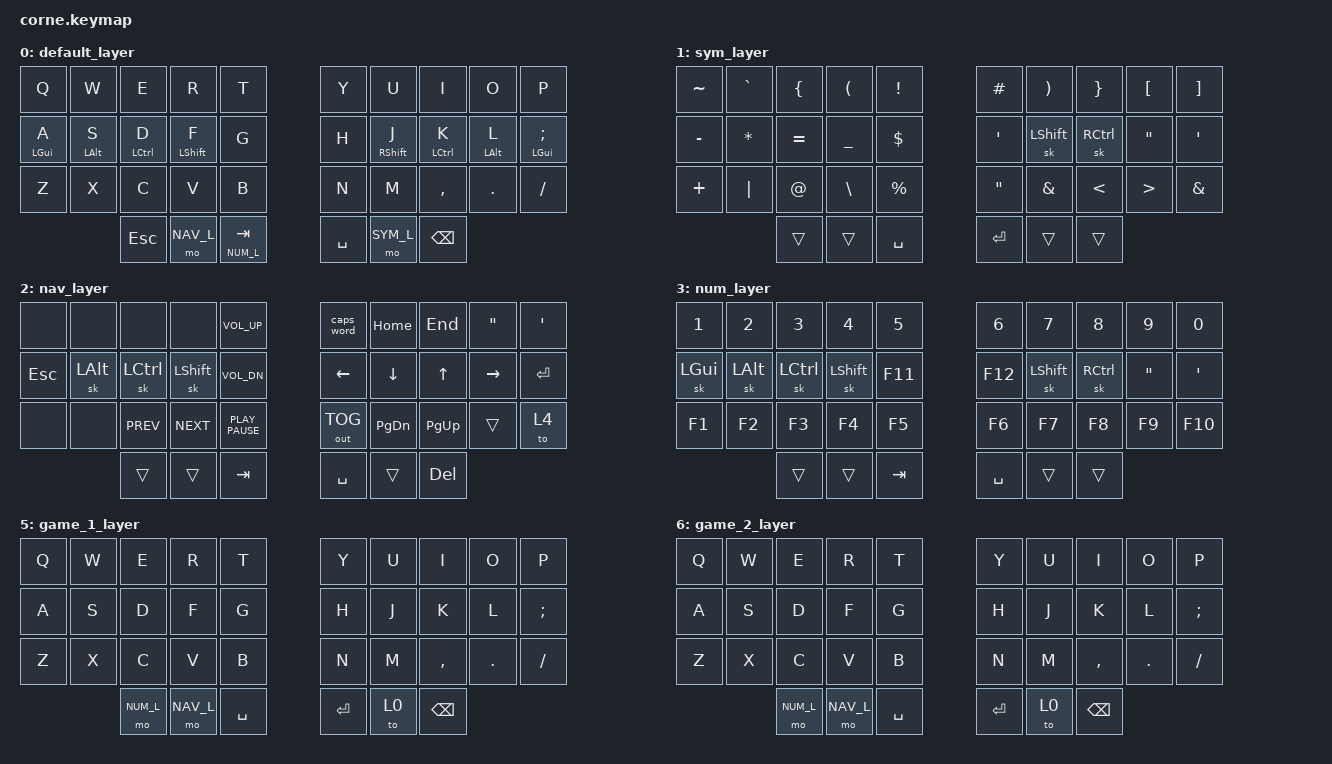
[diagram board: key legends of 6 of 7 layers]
#include <behaviors.dtsi>
#include <dt-bindings/zmk/keys.h>
#include <dt-bindings/zmk/bt.h>
#include <dt-bindings/zmk/outputs.h>

#define QUICK_TAP_MS 175

#define XXX &none
#define ___ &trans

&sk {  // sticky-key config
    release-after-ms = <900>;  // release after 0.6s
    quick-release;             // no double capitalization when rolling keys
};

&sl {  // sticky-layer config
    ignore-modifiers;          // allow chording sticky mods & layers
};

&lt {  // layer-tap config
    flavor = "balanced";
    tapping-term-ms = <200>;
    quick-tap-ms = <QUICK_TAP_MS>;
};

&caps_word {
    continue-list = <UNDERSCORE MINUS>;
};

#include "keys.h"
#define KEYS_L LT0 LT1 LT2 LT3 LT4 LM0 LM1 LM2 LM3 LM4 LB0 LB1 LB2 LB3 LB4  // left hand
#define KEYS_R RT0 RT1 RT2 RT3 RT4 RM0 RM1 RM2 RM3 RM4 RB0 RB1 RB2 RB3 RB4  // right hand
#define THUMBS LH2 LH1 LH0 RH0 RH1 RH2                                      // thumbs

#define _BT_SEL_KEYS_1_ &bt BT_SEL 0 &bt BT_SEL 1 &bt BT_SEL 2  &bt BT_SEL 3
#define _BT_SEL_KEYS_2_ &bt BT_CLR_ALL &bt BT_CLR

#define DEF_L 0 
#define SYM_L 1 
#define NAV_L 2 
#define NUM_L 3 
#define CON_L 4 
#define GAME_1_L 5 
#define GAME_2_L 6 


/ {

    chosen { zmk,matrix_transform = &five_column_transform; };

    behaviors {
        hml: hml {
            compatible = "zmk,behavior-hold-tap";
            #binding-cells = <2>;
            flavor = "balanced";
            tapping-term-ms = <280>;
            quick-tap-ms = <QUICK_TAP_MS>;
            require-prior-idle-ms = <75>;
            bindings = <&kp>, <&kp>;
            hold-trigger-key-positions = <KEYS_R THUMBS>;
            hold-trigger-on-release;
        };


        hmr: hmr {
            compatible = "zmk,behavior-hold-tap";
            #binding-cells = <2>;
            flavor = "balanced";
            tapping-term-ms = <280>;
            quick-tap-ms = <QUICK_TAP_MS>;
            require-prior-idle-ms = <75>;
            bindings = <&kp>, <&kp>;
            hold-trigger-key-positions = <KEYS_L THUMBS>;
            hold-trigger-on-release;
        };
    };

    keymap {
        compatible = "zmk,keymap";

        default_layer {
// ----------------------------------------------------------------------------
// |  Q  |  W  |  E  |  R  |  T  |   |  Y  |  U   |  I   |  O  |  P  |
// |  A  |  S  |  D  |  F  |  G  |   |  H  |  J   |  K   |  L  |  ;  |
// |  Z  |  X  |  C  |  V  |  B  |   |  N  |  M   |  ,   |  .  |  /  |
//             | esc | LWR | tab |   | spc | RSE  | bksp |
        bindings = <
   &kp Q       &kp W       &kp E         &kp R        &kp T           &kp Y     &kp U        &kp I        &kp O       &kp P   
   &hml LGUI A &hml LALT S &hml LCTRL D  &hml LSHFT F &kp G           &kp H     &hmr RSHFT J &hmr LCTRL K &hmr LALT L &hmr LGUI SEMI
   &kp Z       &kp X       &kp C         &kp V        &kp B           &kp N     &kp M        &kp COMMA    &kp DOT     &kp FSLH
                           &kp ESC       &mo NAV_L    &lt NUM_L TAB   &kp SPACE &mo SYM_L    &kp BSPC
                   >;
        };

        sym_layer {

// ---------------------------------------------------------------------------
// | esc | ~   | `   | ( | {   |   | }    | )   | [    | ]    | ^     |
// | -   | *   | =   | _ | $   |   | #    | cmd | alt  | ctrl | shift |
// | +   | "|" | @   | \ | %   |   | none | !   | &    | '    | "     |
//             | esc |   | tab |   | spc  |     | bspc |


            bindings = <
   &kp TILDE  &kp GRAVE  &kp LBRC   &kp LPAR   &kp EXCL   &kp HASH &kp RPAR    &kp RBRC   &kp LBKT  &kp RBKT
   &kp MINUS  &kp ASTRK  &kp EQUAL  &kp UNDER  &kp DLLR   &kp SQT  &sk LSHIFT  &sk RCTRL  &kp DQT   &kp SQT
   &kp PLUS   &kp PIPE   &kp AT     &kp BSLH   &kp PRCNT  &kp DQT  &kp AMPS    &kp LT     &kp GT    &kp AMPS  
                         ___        ___        &kp SPACE  &kp RET   ___         ___
                       >;
        };

        nav_layer {
// ---------------------------------------------------------------------------
// | bt0  | bt1  | bt2  | bt3  | volup |   | cpsword | home | end  | del | bspc |
// | esc  | alt  | ctrl | shft | voldn |   | <-      | down | up   | ->  | ret  |
// | btca | btcl | kprv | knxt | kply  |   |         | pgdn | pgup | sqt | dqt  |
//               | esc  |      | tab   |   | spc     |      | bspc |

            bindings = <
    XXX     XXX       XXX         XXX         &kp K_VOL_UP     &caps_word   &kp HOME  &kp END   &kp DQT   &kp SQT
    &kp ESC &sk LALT  &sk LCTRL   &sk LSHIFT  &kp K_VOL_DN     &kp LEFT     &kp DOWN  &kp UP    &kp RIGHT &kp RET
    XXX     XXX       &kp K_PREV  &kp K_NEXT  &kp K_PLAY_PAUSE &out OUT_TOG &kp PG_DN &kp PG_UP ___       &to 4
                         ___         ___         &kp TAB          &kp SPACE    ___       &kp DEL
                       >;
        };

        num_layer {
// -------------------------------------------------------------------------------
// |  1   |   2  |   3   |    4   |  5  |   | 6   | 7      | 8     | 9    | 0    |
// | lgui | lalt | lctrl | lshift | f11 |   | f12 | lshift | rctrl | ralt | rgui |
// | f1   | f2   | f3    | f4     | f5  |   | f6  | f7     | f8    | f9   | f0   |
//               | esc   |        | tab |   | spc |        | bspc |
            bindings = <
   &kp N1   &kp N2   &kp N3    &kp N4     &kp N5         &kp N6    &kp N7     &kp N8    &kp N9   &kp N0 
   &sk LGUI &sk LALT &sk LCTRL &sk LSHIFT &kp F11        &kp F12   &sk LSHIFT &sk RCTRL &kp DQT  &kp SQT
   &kp F1   &kp F2   &kp F3    &kp F4     &kp F5         &kp F6    &kp F7     &kp F8    &kp F9   &kp F10 
                     ___       ___        &kp TAB        &kp SPACE ___        ___
                       >;
        };


        control_layer {
            bindings = <
   _BT_SEL_KEYS_1_                       &none       &to GAME_1_L &to GAME_2_L &none &none &none &none   
   &none       &none &none     &none     &none       &none        &none        &none &none &none
   _BT_SEL_KEYS_2_   &none     &none     &none       &none        &none        &none &none &none
                     &mo NUM_L &mo NAV_L &kp SPACE   &kp RET      &to 0        &none
            >;
        };

        game_1_layer {
// ----------------------------------------------------------------------------
// |  Q  |  W  |  E  |  R  |  T  |   |  Y  |  U   |  I   |  O  |  P  |
// |  A  |  S  |  D  |  F  |  G  |   |  H  |  J   |  K   |  L  |  ;  |
// |  Z  |  X  |  C  |  V  |  B  |   |  N  |  M   |  ,   |  .  |  /  |
//             | esc | LWR | tab |   | spc | RSE  | bksp |
        bindings = <
   &kp Q       &kp W       &kp E        &kp R        &kp T     &kp Y     &kp U        &kp I        &kp O       &kp P   
   &kp A       &kp S       &kp D        &kp F        &kp G     &kp H     &kp J        &kp K        &kp L       &kp SEMI
   &kp Z       &kp X       &kp C        &kp V        &kp B     &kp N     &kp M        &kp COMMA    &kp DOT     &kp FSLH
                           &mo NUM_L    &mo NAV_L    &kp SPACE &kp RET   &to 0        &kp BSPC
                   >;
        };

        game_2_layer {
// ----------------------------------------------------------------------------
// |  Q  |  W  |  E  |  R  |  T  |   |  Y  |  U   |  I   |  O  |  P  |
// |  A  |  S  |  D  |  F  |  G  |   |  H  |  J   |  K   |  L  |  ;  |
// |  Z  |  X  |  C  |  V  |  B  |   |  N  |  M   |  ,   |  .  |  /  |
//             | esc | LWR | tab |   | spc | RSE  | bksp |
        bindings = <
   &kp Q       &kp W       &kp E        &kp R        &kp T     &kp Y     &kp U        &kp I        &kp O       &kp P   
   &kp A       &kp S       &kp D        &kp F        &kp G     &kp H     &kp J        &kp K        &kp L       &kp SEMI
   &kp Z       &kp X       &kp C        &kp V        &kp B     &kp N     &kp M        &kp COMMA    &kp DOT     &kp FSLH
                           &mo NUM_L    &mo NAV_L    &kp SPACE &kp RET   &to 0        &kp BSPC
                   >;
        };
    };
};

/* vim: set tw=174: */
